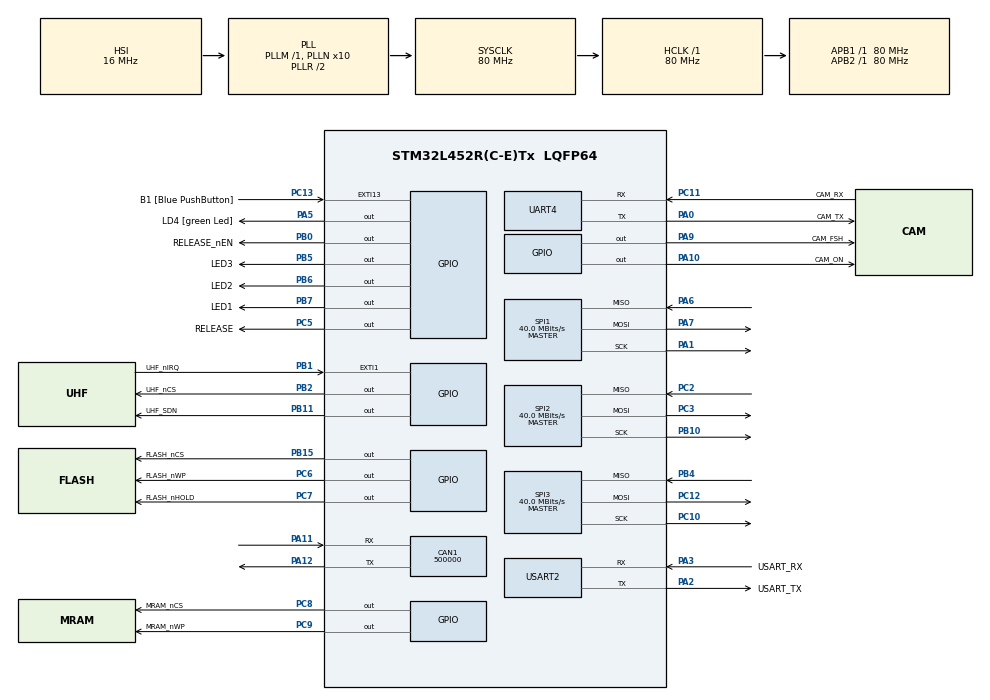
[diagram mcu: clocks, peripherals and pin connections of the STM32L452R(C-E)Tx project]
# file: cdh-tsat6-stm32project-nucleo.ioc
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CAN1.BS1=CAN_BS1_5TQ
CAN1.BS2=CAN_BS2_4TQ
CAN1.CalculateBaudRate=500000
CAN1.CalculateTimeBit=2000
CAN1.CalculateTimeQuantum=200.0
Mcu.Family=STM32L4
Mcu.Name=STM32L452R(C-E)Tx
Mcu.Package=LQFP64
NVIC.PriorityGroup=NVIC_PRIORITYGROUP_4
PA0.GPIO_Label=CAM_TX
PA0.Mode=Asynchronous
PA0.Signal=UART4_TX
PA1.Mode=Full_Duplex_Master
PA1.Signal=SPI1_SCK
PA10.GPIO_Label=CAM_ON
PA10.Signal=GPIO_Output
PA11.Mode=CAN_Activate
PA11.Signal=CAN1_RX
PA12.Mode=CAN_Activate
PA12.Signal=CAN1_TX
PA13\ (JTMS/SWDIO).GPIO_Label=TMS
PA13\ (JTMS/SWDIO).Mode=Serial_Wire
PA13\ (JTMS/SWDIO).Signal=SYS_JTMS-SWDIO
PA14\ (JTCK/SWCLK).GPIO_Label=TCK
PA14\ (JTCK/SWCLK).Mode=Serial_Wire
PA14\ (JTCK/SWCLK).Signal=SYS_JTCK-SWCLK
PA2.GPIO_Label=USART_TX
PA2.GPIO_Mode=GPIO_MODE_AF_PP
PA2.GPIO_PuPd=GPIO_NOPULL
PA2.GPIO_Speed=GPIO_SPEED_FREQ_VERY_HIGH
PA2.Mode=Asynchronous
PA2.Signal=USART2_TX
PA3.GPIO_Label=USART_RX
PA3.GPIO_Mode=GPIO_MODE_AF_PP
PA3.GPIO_PuPd=GPIO_NOPULL
PA3.GPIO_Speed=GPIO_SPEED_FREQ_VERY_HIGH
PA3.Mode=Asynchronous
PA3.Signal=USART2_RX
PA5.GPIO_Label=LD4 [green Led]
PA5.GPIO_ModeDefaultOutputPP=GPIO_MODE_OUTPUT_PP
PA5.GPIO_PuPd=GPIO_NOPULL
PA5.GPIO_Speed=GPIO_SPEED_FREQ_LOW
PA5.Signal=GPIO_Output
PA6.Mode=Full_Duplex_Master
PA6.Signal=SPI1_MISO
PA7.Mode=Full_Duplex_Master
PA7.Signal=SPI1_MOSI
PA9.GPIO_Label=CAM_FSH
PA9.Signal=GPIO_Output
PB0.GPIO_Label=RELEASE_nEN
PB0.Signal=GPIO_Output
PB1.GPIO_Label=UHF_nIRQ
PB1.Signal=GPXTI1
PB10.Mode=Full_Duplex_Master
PB10.Signal=SPI2_SCK
PB11.GPIO_Label=UHF_SDN
PB11.Signal=GPIO_Output
PB15.GPIO_Label=FLASH_nCS
PB15.Signal=GPIO_Output
PB2.GPIO_Label=UHF_nCS
PB2.Signal=GPIO_Output
PB3\ (JTDO/TRACESWO).GPIO_Label=SWO
PB3\ (JTDO/TRACESWO).Signal=SYS_JTDO-SWO
PB4\ (NJTRST).Mode=Full_Duplex_Master
PB4\ (NJTRST).Signal=SPI3_MISO
PB5.GPIO_Label=LED3
PB5.Signal=GPIO_Output
PB6.GPIO_Label=LED2
PB6.Signal=GPIO_Output
PB7.GPIO_Label=LED1
PB7.Signal=GPIO_Output
PC10.Mode=Full_Duplex_Master
PC10.Signal=SPI3_SCK
PC11.GPIO_Label=CAM_RX
PC11.Mode=Asynchronous
PC11.Signal=UART4_RX
PC12.Mode=Full_Duplex_Master
PC12.Signal=SPI3_MOSI
PC13.GPIO_Label=B1 [Blue PushButton]
PC13.GPIO_ModeDefaultEXTI=GPIO_MODE_IT_FALLING
PC13.GPIO_PuPd=GPIO_NOPULL
PC13.Signal=GPXTI13
PC14-OSC32_IN\ (PC14).Mode=LSE-External-Oscillator
PC14-OSC32_IN\ (PC14).Signal=RCC_OSC32_IN
PC15-OSC32_OUT\ (PC15).Mode=LSE-External-Oscillator
PC15-OSC32_OUT\ (PC15).Signal=RCC_OSC32_OUT
PC2.Mode=Full_Duplex_Master
PC2.Signal=SPI2_MISO
PC3.Mode=Full_Duplex_Master
PC3.Signal=SPI2_MOSI
PC5.GPIO_Label=RELEASE
PC5.Signal=GPIO_Output
PC6.GPIO_Label=FLASH_nWP
PC6.Signal=GPIO_Output
PC7.GPIO_Label=FLASH_nHOLD
PC7.Signal=GPIO_Output
PC8.GPIO_Label=MRAM_nCS
PC8.Signal=GPIO_Output
PC9.GPIO_Label=MRAM_nWP
PC9.Signal=GPIO_Output
PH0-OSC_IN\ (PH0).Signal=RCC_OSC_IN
PH1-OSC_OUT\ (PH1).Signal=RCC_OSC_OUT
ProjectManager.HeapSize=0x200
ProjectManager.StackSize=0x400
ProjectManager.TargetToolchain=STM32CubeIDE
RCC.ADCFreq_Value=64000000
RCC.AHBFreq_Value=80000000
RCC.APB1Freq_Value=80000000
RCC.APB1TimFreq_Value=80000000
RCC.APB2Freq_Value=80000000
RCC.APB2TimFreq_Value=80000000
RCC.CortexFreq_Value=80000000
RCC.HCLKFreq_Value=80000000
RCC.HSE_VALUE=8000000
RCC.HSI48_VALUE=48000000
RCC.HSI_VALUE=16000000
RCC.MSI_VALUE=4000000
RCC.PLLN=10
RCC.PLLSourceVirtual=RCC_PLLSOURCE_HSI
RCC.PREFETCH_ENABLE=1
RCC.SYSCLKFreq_VALUE=80000000
RCC.SYSCLKSource=RCC_SYSCLKSOURCE_PLLCLK
RCC.USBFreq_Value=64000000
RCC.VCOOutputFreq_Value=160000000
SPI1.CalculateBaudRate=40.0 MBits/s
SPI1.DataSize=SPI_DATASIZE_8BIT
SPI1.Direction=SPI_DIRECTION_2LINES
SPI1.Mode=SPI_MODE_MASTER
SPI1.VirtualType=VM_MASTER
SPI2.CalculateBaudRate=40.0 MBits/s
SPI2.DataSize=SPI_DATASIZE_8BIT
SPI2.Direction=SPI_DIRECTION_2LINES
SPI2.Mode=SPI_MODE_MASTER
SPI2.VirtualType=VM_MASTER
SPI3.CalculateBaudRate=40.0 MBits/s
SPI3.DataSize=SPI_DATASIZE_8BIT
SPI3.Direction=SPI_DIRECTION_2LINES
SPI3.Mode=SPI_MODE_MASTER
SPI3.VirtualType=VM_MASTER
USART2.VirtualMode-Asynchronous=VM_ASYNC
VP_RTC_VS_RTC_Activate.Mode=RTC_Enabled
board=NUCLEO-L452RE

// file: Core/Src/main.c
/* USER CODE BEGIN Header */
/**
  ******************************************************************************
  * @file           : main.c
  * @brief          : Main program body
  ******************************************************************************
  * @attention
  *
  * Copyright (c) 2022 STMicroelectronics.
  * All rights reserved.
  *
  * This software is licensed under terms that can be found in the LICENSE file
  * in the root directory of this software component.
  * If no LICENSE file comes with this software, it is provided AS-IS.
  *
  ******************************************************************************
  */
/* USER CODE END Header */
#include "main.h"

/* USER CODE BEGIN Includes */
#include "can.h"
/* USER CODE END Includes */

CAN_HandleTypeDef hcan1;

RTC_HandleTypeDef hrtc;

SPI_HandleTypeDef hspi1;
SPI_HandleTypeDef hspi2;
SPI_HandleTypeDef hspi3;

UART_HandleTypeDef huart4;
UART_HandleTypeDef huart2;

void SystemClock_Config(void);
static void MX_GPIO_Init(void);
static void MX_USART2_UART_Init(void);
static void MX_SPI1_Init(void);
static void MX_CAN1_Init(void);
static void MX_SPI2_Init(void);
static void MX_SPI3_Init(void);
static void MX_UART4_Init(void);
static void MX_RTC_Init(void);

int main(void)
{

  /* MCU Configuration--------------------------------------------------------*/

  /* Reset of all peripherals, Initializes the Flash interface and the Systick. */
  HAL_Init();

  /* Configure the system clock */
  SystemClock_Config();

  /* Initialize all configured peripherals */
  MX_GPIO_Init();
  MX_USART2_UART_Init();
  MX_SPI1_Init();
  MX_CAN1_Init();
  MX_SPI2_Init();
  MX_SPI3_Init();
  MX_UART4_Init();
  MX_RTC_Init();
  /* USER CODE BEGIN 2 */
  	  CANMessage_t testMessage;
  	  testMessage.DestinationID = 0x3;
  	  testMessage.command = 0x1;
  	  for(uint8_t index = 0; index >= 7; index++){
  		  testMessage.data[index] = index;
  	  }
  	  testMessage.priority = 0x1;
  /* USER CODE END 2 */

  /* Infinite loop */
  /* USER CODE BEGIN WHILE */
  while (1)
  {
	  CAN_Transmit_Message(testMessage);
	  HAL_Delay(500);
    /* USER CODE END WHILE */

  }
}

void SystemClock_Config(void)
{
  RCC_OscInitTypeDef RCC_OscInitStruct = {0};
  RCC_ClkInitTypeDef RCC_ClkInitStruct = {0};

  /** Configure the main internal regulator output voltage
  */
  if (HAL_PWREx_ControlVoltageScaling(PWR_REGULATOR_VOLTAGE_SCALE1) != HAL_OK)
  {
    Error_Handler();
  }

  /** Initializes the RCC Oscillators according to the specified parameters
  * in the RCC_OscInitTypeDef structure.
  */
  RCC_OscInitStruct.OscillatorType = RCC_OSCILLATORTYPE_HSI|RCC_OSCILLATORTYPE_LSI;
  RCC_OscInitStruct.HSIState = RCC_HSI_ON;
  RCC_OscInitStruct.HSICalibrationValue = RCC_HSICALIBRATION_DEFAULT;
  RCC_OscInitStruct.LSIState = RCC_LSI_ON;
  RCC_OscInitStruct.PLL.PLLState = RCC_PLL_ON;
  RCC_OscInitStruct.PLL.PLLSource = RCC_PLLSOURCE_HSI;
  RCC_OscInitStruct.PLL.PLLM = 1;
  RCC_OscInitStruct.PLL.PLLN = 10;
  RCC_OscInitStruct.PLL.PLLP = RCC_PLLP_DIV7;
  RCC_OscInitStruct.PLL.PLLQ = RCC_PLLQ_DIV2;
  RCC_OscInitStruct.PLL.PLLR = RCC_PLLR_DIV2;
  if (HAL_RCC_OscConfig(&RCC_OscInitStruct) != HAL_OK)
  {
    Error_Handler();
  }

  /** Initializes the CPU, AHB and APB buses clocks
  */
  RCC_ClkInitStruct.ClockType = RCC_CLOCKTYPE_HCLK|RCC_CLOCKTYPE_SYSCLK
                              |RCC_CLOCKTYPE_PCLK1|RCC_CLOCKTYPE_PCLK2;
  RCC_ClkInitStruct.SYSCLKSource = RCC_SYSCLKSOURCE_PLLCLK;
  RCC_ClkInitStruct.AHBCLKDivider = RCC_SYSCLK_DIV1;
  RCC_ClkInitStruct.APB1CLKDivider = RCC_HCLK_DIV1;
  RCC_ClkInitStruct.APB2CLKDivider = RCC_HCLK_DIV1;

  if (HAL_RCC_ClockConfig(&RCC_ClkInitStruct, FLASH_LATENCY_4) != HAL_OK)
  {
    Error_Handler();
  }
}

static void MX_CAN1_Init(void)
{

  hcan1.Instance = CAN1;
  hcan1.Init.Prescaler = 16;
  hcan1.Init.Mode = CAN_MODE_NORMAL;
  hcan1.Init.SyncJumpWidth = CAN_SJW_1TQ;
  hcan1.Init.TimeSeg1 = CAN_BS1_5TQ;
  hcan1.Init.TimeSeg2 = CAN_BS2_4TQ;
  hcan1.Init.TimeTriggeredMode = DISABLE;
  hcan1.Init.AutoBusOff = DISABLE;
  hcan1.Init.AutoWakeUp = DISABLE;
  hcan1.Init.AutoRetransmission = DISABLE;
  hcan1.Init.ReceiveFifoLocked = DISABLE;
  hcan1.Init.TransmitFifoPriority = DISABLE;
  if (HAL_CAN_Init(&hcan1) != HAL_OK)
  {
    Error_Handler();
  }
  /* USER CODE BEGIN CAN1_Init 2 */
  Boot_CAN();
  /* USER CODE END CAN1_Init 2 */

}

static void MX_RTC_Init(void)
{

  /** Initialize RTC Only
  */
  hrtc.Instance = RTC;
  hrtc.Init.HourFormat = RTC_HOURFORMAT_24;
  hrtc.Init.AsynchPrediv = 127;
  hrtc.Init.SynchPrediv = 255;
  hrtc.Init.OutPut = RTC_OUTPUT_DISABLE;
  hrtc.Init.OutPutRemap = RTC_OUTPUT_REMAP_NONE;
  hrtc.Init.OutPutPolarity = RTC_OUTPUT_POLARITY_HIGH;
  hrtc.Init.OutPutType = RTC_OUTPUT_TYPE_OPENDRAIN;
  if (HAL_RTC_Init(&hrtc) != HAL_OK)
  {
    Error_Handler();
  }

}

static void MX_SPI1_Init(void)
{

  /* SPI1 parameter configuration*/
  hspi1.Instance = SPI1;
  hspi1.Init.Mode = SPI_MODE_MASTER;
  hspi1.Init.Direction = SPI_DIRECTION_2LINES;
  hspi1.Init.DataSize = SPI_DATASIZE_8BIT;
  hspi1.Init.CLKPolarity = SPI_POLARITY_LOW;
  hspi1.Init.CLKPhase = SPI_PHASE_1EDGE;
  hspi1.Init.NSS = SPI_NSS_SOFT;
  hspi1.Init.BaudRatePrescaler = SPI_BAUDRATEPRESCALER_2;
  hspi1.Init.FirstBit = SPI_FIRSTBIT_MSB;
  hspi1.Init.TIMode = SPI_TIMODE_DISABLE;
  hspi1.Init.CRCCalculation = SPI_CRCCALCULATION_DISABLE;
  hspi1.Init.CRCPolynomial = 7;
  hspi1.Init.CRCLength = SPI_CRC_LENGTH_DATASIZE;
  hspi1.Init.NSSPMode = SPI_NSS_PULSE_ENABLE;
  if (HAL_SPI_Init(&hspi1) != HAL_OK)
  {
    Error_Handler();
  }

}

static void MX_SPI2_Init(void)
{

  /* SPI2 parameter configuration*/
  hspi2.Instance = SPI2;
  hspi2.Init.Mode = SPI_MODE_MASTER;
  hspi2.Init.Direction = SPI_DIRECTION_2LINES;
  hspi2.Init.DataSize = SPI_DATASIZE_8BIT;
  hspi2.Init.CLKPolarity = SPI_POLARITY_LOW;
  hspi2.Init.CLKPhase = SPI_PHASE_1EDGE;
  hspi2.Init.NSS = SPI_NSS_SOFT;
  hspi2.Init.BaudRatePrescaler = SPI_BAUDRATEPRESCALER_2;
  hspi2.Init.FirstBit = SPI_FIRSTBIT_MSB;
  hspi2.Init.TIMode = SPI_TIMODE_DISABLE;
  hspi2.Init.CRCCalculation = SPI_CRCCALCULATION_DISABLE;
  hspi2.Init.CRCPolynomial = 7;
  hspi2.Init.CRCLength = SPI_CRC_LENGTH_DATASIZE;
  hspi2.Init.NSSPMode = SPI_NSS_PULSE_ENABLE;
  if (HAL_SPI_Init(&hspi2) != HAL_OK)
  {
    Error_Handler();
  }

}

static void MX_SPI3_Init(void)
{

  /* SPI3 parameter configuration*/
  hspi3.Instance = SPI3;
  hspi3.Init.Mode = SPI_MODE_MASTER;
  hspi3.Init.Direction = SPI_DIRECTION_2LINES;
  hspi3.Init.DataSize = SPI_DATASIZE_8BIT;
  hspi3.Init.CLKPolarity = SPI_POLARITY_LOW;
  hspi3.Init.CLKPhase = SPI_PHASE_1EDGE;
  hspi3.Init.NSS = SPI_NSS_SOFT;
  hspi3.Init.BaudRatePrescaler = SPI_BAUDRATEPRESCALER_2;
  hspi3.Init.FirstBit = SPI_FIRSTBIT_MSB;
  hspi3.Init.TIMode = SPI_TIMODE_DISABLE;
  hspi3.Init.CRCCalculation = SPI_CRCCALCULATION_DISABLE;
  hspi3.Init.CRCPolynomial = 7;
  hspi3.Init.CRCLength = SPI_CRC_LENGTH_DATASIZE;
  hspi3.Init.NSSPMode = SPI_NSS_PULSE_ENABLE;
  if (HAL_SPI_Init(&hspi3) != HAL_OK)
  {
    Error_Handler();
  }

}

static void MX_UART4_Init(void)
{

  huart4.Instance = UART4;
  huart4.Init.BaudRate = 115200;
  huart4.Init.WordLength = UART_WORDLENGTH_8B;
  huart4.Init.StopBits = UART_STOPBITS_1;
  huart4.Init.Parity = UART_PARITY_NONE;
  huart4.Init.Mode = UART_MODE_TX_RX;
  huart4.Init.HwFlowCtl = UART_HWCONTROL_NONE;
  huart4.Init.OverSampling = UART_OVERSAMPLING_16;
  huart4.Init.OneBitSampling = UART_ONE_BIT_SAMPLE_DISABLE;
  huart4.AdvancedInit.AdvFeatureInit = UART_ADVFEATURE_NO_INIT;
  if (HAL_UART_Init(&huart4) != HAL_OK)
  {
    Error_Handler();
  }

}

static void MX_USART2_UART_Init(void)
{

  huart2.Instance = USART2;
  huart2.Init.BaudRate = 115200;
  huart2.Init.WordLength = UART_WORDLENGTH_8B;
  huart2.Init.StopBits = UART_STOPBITS_1;
  huart2.Init.Parity = UART_PARITY_NONE;
  huart2.Init.Mode = UART_MODE_TX_RX;
  huart2.Init.HwFlowCtl = UART_HWCONTROL_NONE;
  huart2.Init.OverSampling = UART_OVERSAMPLING_16;
  huart2.Init.OneBitSampling = UART_ONE_BIT_SAMPLE_DISABLE;
  huart2.AdvancedInit.AdvFeatureInit = UART_ADVFEATURE_NO_INIT;
  if (HAL_UART_Init(&huart2) != HAL_OK)
  {
    Error_Handler();
  }

}

static void MX_GPIO_Init(void)
{
  GPIO_InitTypeDef GPIO_InitStruct = {0};

  /* GPIO Ports Clock Enable */
  __HAL_RCC_GPIOC_CLK_ENABLE();
  __HAL_RCC_GPIOH_CLK_ENABLE();
  __HAL_RCC_GPIOA_CLK_ENABLE();
  __HAL_RCC_GPIOB_CLK_ENABLE();

  /*Configure GPIO pin Output Level */
  HAL_GPIO_WritePin(GPIOA, LD4_Pin|CAM_FSH_Pin|CAM_ON_Pin, GPIO_PIN_RESET);

  /*Configure GPIO pin Output Level */
  HAL_GPIO_WritePin(GPIOC, RELEASE_Pin|FLASH_nWP_Pin|FLASH_nHOLD_Pin|MRAM_nCS_Pin
                          |MRAM_nWP_Pin, GPIO_PIN_RESET);

  /*Configure GPIO pin Output Level */
  HAL_GPIO_WritePin(GPIOB, RELEASE_nEN_Pin|UHF_nCS_Pin|UHF_SDN_Pin|FLASH_nCS_Pin
                          |LED3_Pin|LED2_Pin|LED1_Pin, GPIO_PIN_RESET);

  /*Configure GPIO pin : B1_Pin */
  GPIO_InitStruct.Pin = B1_Pin;
  GPIO_InitStruct.Mode = GPIO_MODE_IT_FALLING;
  GPIO_InitStruct.Pull = GPIO_NOPULL;
  HAL_GPIO_Init(B1_GPIO_Port, &GPIO_InitStruct);

  /*Configure GPIO pins : LD4_Pin CAM_FSH_Pin CAM_ON_Pin */
  GPIO_InitStruct.Pin = LD4_Pin|CAM_FSH_Pin|CAM_ON_Pin;
  GPIO_InitStruct.Mode = GPIO_MODE_OUTPUT_PP;
  GPIO_InitStruct.Pull = GPIO_NOPULL;
  GPIO_InitStruct.Speed = GPIO_SPEED_FREQ_LOW;
  HAL_GPIO_Init(GPIOA, &GPIO_InitStruct);

  /*Configure GPIO pins : RELEASE_Pin FLASH_nWP_Pin FLASH_nHOLD_Pin MRAM_nCS_Pin
                           MRAM_nWP_Pin */
  GPIO_InitStruct.Pin = RELEASE_Pin|FLASH_nWP_Pin|FLASH_nHOLD_Pin|MRAM_nCS_Pin
                          |MRAM_nWP_Pin;
  GPIO_InitStruct.Mode = GPIO_MODE_OUTPUT_PP;
  GPIO_InitStruct.Pull = GPIO_NOPULL;
  GPIO_InitStruct.Speed = GPIO_SPEED_FREQ_LOW;
  HAL_GPIO_Init(GPIOC, &GPIO_InitStruct);

  /*Configure GPIO pins : RELEASE_nEN_Pin UHF_nCS_Pin UHF_SDN_Pin FLASH_nCS_Pin
                           LED3_Pin LED2_Pin LED1_Pin */
  GPIO_InitStruct.Pin = RELEASE_nEN_Pin|UHF_nCS_Pin|UHF_SDN_Pin|FLASH_nCS_Pin
                          |LED3_Pin|LED2_Pin|LED1_Pin;
  GPIO_InitStruct.Mode = GPIO_MODE_OUTPUT_PP;
  GPIO_InitStruct.Pull = GPIO_NOPULL;
  GPIO_InitStruct.Speed = GPIO_SPEED_FREQ_LOW;
  HAL_GPIO_Init(GPIOB, &GPIO_InitStruct);

  /*Configure GPIO pin : UHF_nIRQ_Pin */
  GPIO_InitStruct.Pin = UHF_nIRQ_Pin;
  GPIO_InitStruct.Mode = GPIO_MODE_IT_RISING;
  GPIO_InitStruct.Pull = GPIO_NOPULL;
  HAL_GPIO_Init(UHF_nIRQ_GPIO_Port, &GPIO_InitStruct);

}

/* USER CODE BEGIN 4 */
void HAL_CAN_RxFifo0MsgPendingCallback(CAN_HandleTypeDef *hcan)
{
	CAN_Message_Received();
}
/* USER CODE END 4 */

void Error_Handler(void)
{
  __disable_irq();
  while (1)
  {
  }
}
